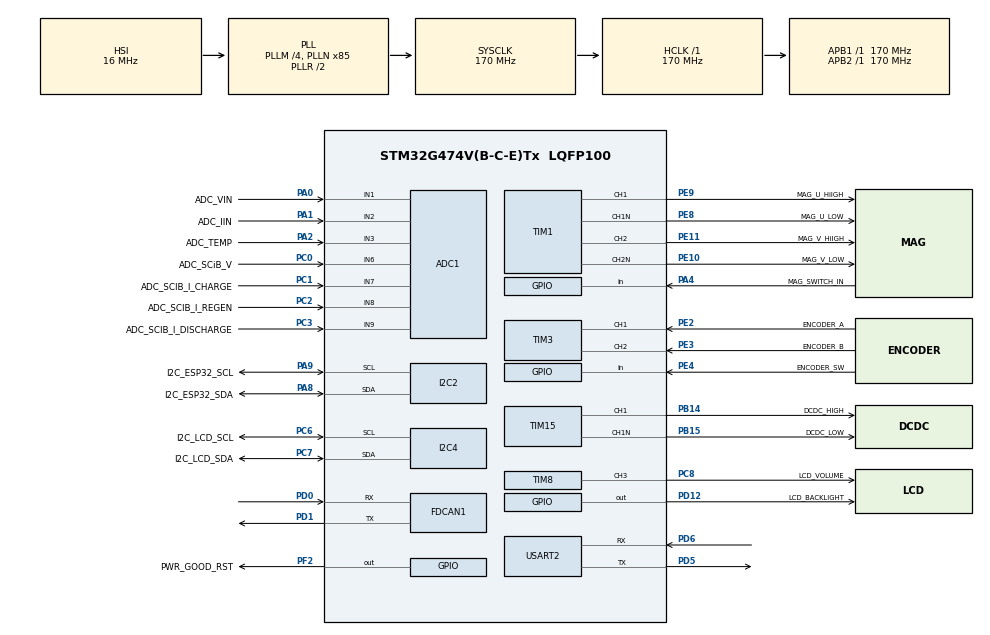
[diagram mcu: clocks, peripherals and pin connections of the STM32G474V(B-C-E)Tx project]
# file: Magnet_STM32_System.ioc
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ADC1.Channel-0\#ChannelRegularConversion=ADC_CHANNEL_6
ADC1.Channel-1\#ChannelRegularConversion=ADC_CHANNEL_7
ADC1.Channel-2\#ChannelRegularConversion=ADC_CHANNEL_8
ADC1.Channel-3\#ChannelRegularConversion=ADC_CHANNEL_9
ADC1.Channel-4\#ChannelRegularConversion=ADC_CHANNEL_1
ADC1.Channel-5\#ChannelRegularConversion=ADC_CHANNEL_2
ADC1.Channel-6\#ChannelRegularConversion=ADC_CHANNEL_3
ADC1.ContinuousConvMode=ENABLE
ADC1.DMAContinuousRequests=ENABLE
ADC1.EOCSelection=ADC_EOC_SINGLE_CONV
ADC1.EnableInjectedConversion=DISABLE
ADC1.ExternalTrigConv=ADC_SOFTWARE_START
ADC1.NbrOfConversion=7
ADC1.NbrOfConversionFlag=1
ADC1.OffsetNumber-0\#ChannelRegularConversion=ADC_OFFSET_NONE
ADC1.OffsetNumber-1\#ChannelRegularConversion=ADC_OFFSET_NONE
ADC1.OffsetNumber-2\#ChannelRegularConversion=ADC_OFFSET_NONE
ADC1.OffsetNumber-3\#ChannelRegularConversion=ADC_OFFSET_NONE
ADC1.OffsetNumber-4\#ChannelRegularConversion=ADC_OFFSET_NONE
ADC1.OffsetNumber-5\#ChannelRegularConversion=ADC_OFFSET_NONE
ADC1.OffsetNumber-6\#ChannelRegularConversion=ADC_OFFSET_NONE
ADC1.OversamplingMode=ENABLE
ADC1.OversamplingStopReset=ADC_REGOVERSAMPLING_CONTINUED_MODE
ADC1.Rank-0\#ChannelRegularConversion=1
ADC1.Rank-1\#ChannelRegularConversion=2
ADC1.Rank-2\#ChannelRegularConversion=3
ADC1.Rank-3\#ChannelRegularConversion=4
ADC1.Rank-4\#ChannelRegularConversion=5
ADC1.Rank-5\#ChannelRegularConversion=6
ADC1.Rank-6\#ChannelRegularConversion=7
ADC1.Ratio=ADC_OVERSAMPLING_RATIO_4
ADC1.SamplingTime-0\#ChannelRegularConversion=ADC_SAMPLETIME_24CYCLES_5
ADC1.SamplingTime-1\#ChannelRegularConversion=ADC_SAMPLETIME_24CYCLES_5
ADC1.SamplingTime-2\#ChannelRegularConversion=ADC_SAMPLETIME_24CYCLES_5
ADC1.SamplingTime-3\#ChannelRegularConversion=ADC_SAMPLETIME_24CYCLES_5
ADC1.SamplingTime-4\#ChannelRegularConversion=ADC_SAMPLETIME_24CYCLES_5
ADC1.SamplingTime-5\#ChannelRegularConversion=ADC_SAMPLETIME_24CYCLES_5
ADC1.SamplingTime-6\#ChannelRegularConversion=ADC_SAMPLETIME_24CYCLES_5
ADC1.master=1
Dma.ADC1.0.Direction=DMA_PERIPH_TO_MEMORY
Dma.ADC1.0.EventEnable=DISABLE
Dma.ADC1.0.Instance=DMA1_Channel1
Dma.ADC1.0.MemDataAlignment=DMA_MDATAALIGN_HALFWORD
Dma.ADC1.0.MemInc=DMA_MINC_ENABLE
Dma.ADC1.0.Mode=DMA_CIRCULAR
Dma.ADC1.0.PeriphDataAlignment=DMA_PDATAALIGN_HALFWORD
Dma.ADC1.0.PeriphInc=DMA_PINC_DISABLE
Dma.ADC1.0.Polarity=HAL_DMAMUX_REQ_GEN_RISING
Dma.ADC1.0.Priority=DMA_PRIORITY_MEDIUM
Dma.ADC1.0.RequestNumber=1
Dma.ADC1.0.SignalID=NONE
Dma.ADC1.0.SyncEnable=DISABLE
Dma.ADC1.0.SyncPolarity=HAL_DMAMUX_SYNC_NO_EVENT
Dma.ADC1.0.SyncRequestNumber=1
Dma.ADC1.0.SyncSignalID=NONE
Dma.Request0=ADC1
FDCAN1.CalculateBaudRateNominal=3541666
FDCAN1.CalculateTimeBitNominal=282
FDCAN1.CalculateTimeQuantumNominal=94.11764705882354
I2C2.Timing=0x40B285C2
I2C4.Timing=0x40B285C2
IWDG.Prescaler=IWDG_PRESCALER_32
IWDG.Reload=1000
IWDG.Window=0xfff
Mcu.Family=STM32G4
Mcu.Name=STM32G474V(B-C-E)Tx
Mcu.Package=LQFP100
NVIC.DMA1_Channel1_IRQn=true\:0\:0\:false\:false\:true\:false\:true\:true
NVIC.PriorityGroup=NVIC_PRIORITYGROUP_4
NVIC.TIM1_BRK_TIM15_IRQn=true\:15\:0\:false\:false\:true\:false\:true\:true
PA0.GPIO_Label=ADC_VIN
PA0.Mode=IN1-Single-Ended
PA0.Signal=ADC1_IN1
PA1.GPIO_Label=ADC_IIN
PA1.Mode=IN2-Single-Ended
PA1.Signal=ADC1_IN2
PA13.Mode=JTAG_5_pins
PA13.Signal=SYS_JTMS-SWDIO
PA14.Mode=JTAG_5_pins
PA14.Signal=SYS_JTCK-SWCLK
PA15.Mode=JTAG_5_pins
PA15.Signal=SYS_JTDI
PA2.GPIO_Label=ADC_TEMP
PA2.Mode=IN3-Single-Ended
PA2.Signal=ADC1_IN3
PA4.GPIO_Label=MAG_SWITCH_IN
PA4.Signal=GPIO_Input
PA8.GPIO_Label=I2C_ESP32_SDA
PA8.Mode=I2C
PA8.Signal=I2C2_SDA
PA9.GPIO_Label=I2C_ESP32_SCL
PA9.Mode=I2C
PA9.Signal=I2C2_SCL
PB14.GPIO_Label=DCDC_HIGH
PB14.Signal=S_TIM15_CH1
PB15.GPIO_Label=DCDC_LOW
PB15.Mode=PWM Generation1 CH1 CH1N
PB15.Signal=TIM15_CH1N
PB3.Mode=JTAG_5_pins
PB3.Signal=SYS_JTDO-SWO
PB4.Mode=JTAG_5_pins
PB4.Signal=SYS_JTRST
PC0.GPIO_Label=ADC_SCiB_V
PC0.Mode=IN6-Single-Ended
PC0.Signal=ADC1_IN6
PC1.GPIO_Label=ADC_SCIB_I_CHARGE
PC1.Mode=IN7-Single-Ended
PC1.Signal=ADC1_IN7
PC14-OSC32_IN.GPIO_Label=LSE_IN
PC14-OSC32_IN.Mode=LSE-External-Oscillator
PC14-OSC32_IN.Signal=RCC_OSC32_IN
PC15-OSC32_OUT.GPIO_Label=LSE_OUT
PC15-OSC32_OUT.Mode=LSE-External-Oscillator
PC15-OSC32_OUT.Signal=RCC_OSC32_OUT
PC2.GPIO_Label=ADC_SCIB_I_REGEN
PC2.Mode=IN8-Single-Ended
PC2.Signal=ADC1_IN8
PC3.GPIO_Label=ADC_SCIB_I_DISCHARGE
PC3.Mode=IN9-Single-Ended
PC3.Signal=ADC1_IN9
PC6.GPIO_Label=I2C_LCD_SCL
PC6.GPIO_Pu=GPIO_PULLUP
PC6.GPIO_Speed=GPIO_SPEED_FREQ_HIGH
PC6.Mode=I2C
PC6.Signal=I2C4_SCL
PC7.GPIO_Label=I2C_LCD_SDA
PC7.GPIO_Pu=GPIO_PULLUP
PC7.GPIO_Speed=GPIO_SPEED_FREQ_HIGH
PC7.Mode=I2C
PC7.Signal=I2C4_SDA
PC8.GPIO_Label=LCD_VOLUME
PC8.Signal=S_TIM8_CH3
PD0.Mode=FDCAN_Activate
PD0.Signal=FDCAN1_RX
PD1.Mode=FDCAN_Activate
PD1.Signal=FDCAN1_TX
PD12.GPIO_Label=LCD_BACKLIGHT
PD12.Signal=GPIO_Output
PD5.Mode=Asynchronous
PD5.Signal=USART2_TX
PD6.Mode=Asynchronous
PD6.Signal=USART2_RX
PE10.GPIO_Label=MAG_V_LOW
PE10.Mode=PWM Generation2 CH2 CH2N
PE10.Signal=TIM1_CH2N
PE11.GPIO_Label=MAG_V_HiIGH
PE11.Signal=S_TIM1_CH2
PE2.GPIO_Label=ENCODER_A
PE2.Signal=S_TIM3_CH1
PE3.GPIO_Label=ENCODER_B
PE3.Signal=S_TIM3_CH2
PE4.GPIO_Label=ENCODER_SW
PE4.Signal=GPIO_Input
PE8.GPIO_Label=MAG_U_LOW
PE8.Mode=PWM Generation1 CH1 CH1N
PE8.Signal=TIM1_CH1N
PE9.GPIO_Label=MAG_U_HiIGH
PE9.Signal=S_TIM1_CH1
PF2.GPIO_Label=PWR_GOOD_RST
PF2.Signal=GPIO_Output
ProjectManager.HeapSize=0x200
ProjectManager.StackSize=0x400
ProjectManager.TargetToolchain=STM32CubeIDE
RCC.ADC12Freq_Value=170000000
RCC.ADC345Freq_Value=170000000
RCC.AHBFreq_Value=170000000
RCC.APB1Freq_Value=170000000
RCC.APB1TimFreq_Value=170000000
RCC.APB2Freq_Value=170000000
RCC.APB2TimCLKDivider=1
RCC.APB2TimFreq_Value=170000000
RCC.CortexFreq_Value=170000000
RCC.EXTERNAL_CLOCK_VALUE=12288000
RCC.HCLKFreq_Value=170000000
RCC.HSE_VALUE=8000000
RCC.HSI48_VALUE=48000000
RCC.HSI_VALUE=16000000
RCC.PLLM=RCC_PLLM_DIV4
RCC.PLLN=85
RCC.SYSCLKFreq_VALUE=170000000
RCC.SYSCLKSource=RCC_SYSCLKSOURCE_PLLCLK
RCC.USBFreq_Value=170000000
RCC.VCOOutputFreq_Value=340000000
SH.S_TIM15_CH1.0=TIM15_CH1,PWM Generation1 CH1 CH1N
SH.S_TIM1_CH1.0=TIM1_CH1,PWM Generation1 CH1 CH1N
SH.S_TIM1_CH2.0=TIM1_CH2,PWM Generation2 CH2 CH2N
SH.S_TIM3_CH1.0=TIM3_CH1,Encoder_Interface
SH.S_TIM3_CH2.0=TIM3_CH2,Encoder_Interface
SH.S_TIM8_CH3.0=TIM8_CH3,PWM Generation3 CH3
TIM1.Channel-PWM\ Generation1\ CH1\ CH1N=TIM_CHANNEL_1
TIM1.Channel-PWM\ Generation2\ CH2\ CH2N=TIM_CHANNEL_2
TIM15.Channel-PWM\ Generation1\ CH1\ CH1N=TIM_CHANNEL_1
TIM8.Channel-PWM\ Generation3\ CH3=TIM_CHANNEL_3
TIM8.PeriodNoDither=200
TIM8.Prescaler=0
USART2.VirtualMode-Asynchronous=VM_ASYNC
VP_FMAC_VS_FMAC.Mode=FMAC_Activate
VP_IWDG_VS_IWDG.Mode=IWDG_Activate
VP_SYS_VS_DBSignals.Mode=DisableDeadBatterySignals
VP_TIM1_VS_ClockSourceINT.Mode=Internal
board=custom

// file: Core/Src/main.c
/* USER CODE BEGIN Header */
/**
  ******************************************************************************
  * @file           : main.c
  * @brief          : Main program body
  ******************************************************************************
  * @attention
  *
  * Copyright (c) 2024 STMicroelectronics.
  * All rights reserved.
  *
  * This software is licensed under terms that can be found in the LICENSE file
  * in the root directory of this software component.
  * If no LICENSE file comes with this software, it is provided AS-IS.
  *
  ******************************************************************************
  */
/* USER CODE END Header */
#include "main.h"
#include "adc.h"
#include "dma.h"
#include "fdcan.h"
#include "fmac.h"
#include "i2c.h"
#include "iwdg.h"
#include "tim.h"
#include "usart.h"
#include "gpio.h"

/* USER CODE BEGIN PV */
#define HAL_IWDG_Init(a)	(HAL_OK)
/* USER CODE END PV */

void SystemClock_Config(void);

int main(void)
{

  /* MCU Configuration--------------------------------------------------------*/

  /* Reset of all peripherals, Initializes the Flash interface and the Systick. */
  HAL_Init();

  /* Configure the system clock */
  SystemClock_Config();

  /* Initialize all configured peripherals */
  MX_GPIO_Init();
  MX_DMA_Init();
  MX_ADC1_Init();
  MX_TIM1_Init();
  MX_TIM3_Init();
  MX_FMAC_Init();
  MX_USART2_UART_Init();
  MX_I2C4_Init();
  MX_TIM8_Init();
  MX_IWDG_Init();
  MX_FDCAN1_Init();
  MX_I2C2_Init();
  MX_TIM15_Init();
  /* USER CODE BEGIN 2 */
  RCC->CSR |= RCC_CSR_RMVF;
  void knl_start_mtkernel(void);
  knl_start_mtkernel();
  /* USER CODE END 2 */

  /* Infinite loop */
  while (1)
  {

  }
}

void SystemClock_Config(void)
{
  RCC_OscInitTypeDef RCC_OscInitStruct = {0};
  RCC_ClkInitTypeDef RCC_ClkInitStruct = {0};

  /** Configure the main internal regulator output voltage
  */
  HAL_PWREx_ControlVoltageScaling(PWR_REGULATOR_VOLTAGE_SCALE1_BOOST);

  /** Initializes the RCC Oscillators according to the specified parameters
  * in the RCC_OscInitTypeDef structure.
  */
  RCC_OscInitStruct.OscillatorType = RCC_OSCILLATORTYPE_HSI|RCC_OSCILLATORTYPE_LSI;
  RCC_OscInitStruct.HSIState = RCC_HSI_ON;
  RCC_OscInitStruct.HSICalibrationValue = RCC_HSICALIBRATION_DEFAULT;
  RCC_OscInitStruct.LSIState = RCC_LSI_ON;
  RCC_OscInitStruct.PLL.PLLState = RCC_PLL_ON;
  RCC_OscInitStruct.PLL.PLLSource = RCC_PLLSOURCE_HSI;
  RCC_OscInitStruct.PLL.PLLM = RCC_PLLM_DIV4;
  RCC_OscInitStruct.PLL.PLLN = 85;
  RCC_OscInitStruct.PLL.PLLP = RCC_PLLP_DIV2;
  RCC_OscInitStruct.PLL.PLLQ = RCC_PLLQ_DIV2;
  RCC_OscInitStruct.PLL.PLLR = RCC_PLLR_DIV2;
  if (HAL_RCC_OscConfig(&RCC_OscInitStruct) != HAL_OK)
  {
    Error_Handler();
  }

  /** Initializes the CPU, AHB and APB buses clocks
  */
  RCC_ClkInitStruct.ClockType = RCC_CLOCKTYPE_HCLK|RCC_CLOCKTYPE_SYSCLK
                              |RCC_CLOCKTYPE_PCLK1|RCC_CLOCKTYPE_PCLK2;
  RCC_ClkInitStruct.SYSCLKSource = RCC_SYSCLKSOURCE_PLLCLK;
  RCC_ClkInitStruct.AHBCLKDivider = RCC_SYSCLK_DIV1;
  RCC_ClkInitStruct.APB1CLKDivider = RCC_HCLK_DIV1;
  RCC_ClkInitStruct.APB2CLKDivider = RCC_HCLK_DIV1;

  if (HAL_RCC_ClockConfig(&RCC_ClkInitStruct, FLASH_LATENCY_4) != HAL_OK)
  {
    Error_Handler();
  }
}

void Error_Handler(void)
{
  __disable_irq();
  while (1)
  {
  }
}
